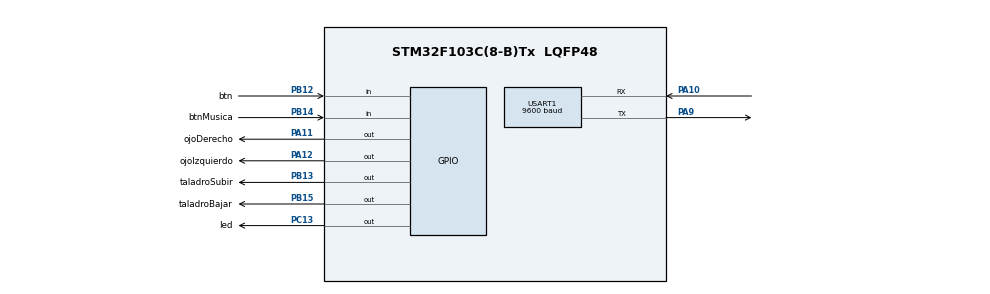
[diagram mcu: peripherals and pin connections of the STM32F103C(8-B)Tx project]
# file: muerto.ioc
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Mcu.Family=STM32F1
Mcu.Name=STM32F103C(8-B)Tx
Mcu.Package=LQFP48
NVIC.PriorityGroup=NVIC_PRIORITYGROUP_4
PA10.Mode=Asynchronous
PA10.Signal=USART1_RX
PA11.GPIO_Label=ojoDerecho
PA11.Signal=GPIO_Output
PA12.GPIO_Label=ojoIzquierdo
PA12.Signal=GPIO_Output
PA13.Mode=Serial_Wire
PA13.Signal=SYS_JTMS-SWDIO
PA14.Mode=Serial_Wire
PA14.Signal=SYS_JTCK-SWCLK
PA9.Mode=Asynchronous
PA9.Signal=USART1_TX
PB12.GPIO_Label=btn
PB12.GPIO_PuPd=GPIO_PULLUP
PB12.Signal=GPIO_Input
PB13.GPIO_Label=taladroSubir
PB13.Signal=GPIO_Output
PB14.GPIO_Label=btnMusica
PB14.GPIO_PuPd=GPIO_PULLUP
PB14.Signal=GPIO_Input
PB15.GPIO_Label=taladroBajar
PB15.Signal=GPIO_Output
PC13-TAMPER-RTC.GPIO_Label=led
PC13-TAMPER-RTC.Signal=GPIO_Output
PD0-OSC_IN.Mode=HSE-External-Oscillator
PD0-OSC_IN.Signal=RCC_OSC_IN
PD1-OSC_OUT.Mode=HSE-External-Oscillator
PD1-OSC_OUT.Signal=RCC_OSC_OUT
ProjectManager.HeapSize=0x200
ProjectManager.StackSize=0x400
ProjectManager.TargetToolchain=STM32CubeIDE
RCC.APB1Freq_Value=8000000
RCC.APB2Freq_Value=8000000
USART1.BaudRate=9600
USART1.VirtualMode=VM_ASYNC
board=custom

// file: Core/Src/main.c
/* USER CODE BEGIN Header */
/**
  ******************************************************************************
  * @file           : main.c
  * @brief          : Main program body
  ******************************************************************************
  * @attention
  *
  * Copyright (c) 2023 STMicroelectronics.
  * All rights reserved.
  *
  * This software is licensed under terms that can be found in the LICENSE file
  * in the root directory of this software component.
  * If no LICENSE file comes with this software, it is provided AS-IS.
  *
  ******************************************************************************
  */
/* USER CODE END Header */
#include "main.h"

/* USER CODE BEGIN Includes */

#include "../librerias/uart.h"
#include "../librerias/dfplayer.h"

/* USER CODE END Includes */

UART_HandleTypeDef huart1;

void SystemClock_Config(void);
static void MX_GPIO_Init(void);
static void MX_USART1_UART_Init(void);

int main(void)
{

  /* MCU Configuration--------------------------------------------------------*/

  /* Reset of all peripherals, Initializes the Flash interface and the Systick. */
  HAL_Init();

  /* Configure the system clock */
  SystemClock_Config();

  /* Initialize all configured peripherals */
  MX_GPIO_Init();
  MX_USART1_UART_Init();
  /* USER CODE BEGIN 2 */
  HAL_GPIO_WritePin(taladroBajar_GPIO_Port, taladroBajar_Pin, 1);
  HAL_GPIO_WritePin(taladroSubir_GPIO_Port, taladroSubir_Pin, 1);
  HAL_GPIO_WritePin(led_GPIO_Port, led_Pin, 1);

  HAL_Delay(500);
   mp3_inicializa();
   HAL_Delay(200);
   mp3_play_x(2);
  /* USER CODE END 2 */

  /* Infinite loop */
   while (1)
      {

    	  if(HAL_GPIO_ReadPin(btn_GPIO_Port, btn_Pin)){
    		  // Si no se presiona el boton todo se desactiva
    		   HAL_GPIO_WritePin(led_GPIO_Port, led_Pin, 1);
    	  		HAL_GPIO_WritePin(taladroBajar_GPIO_Port, taladroBajar_Pin, 1);
    	  		HAL_GPIO_WritePin(taladroSubir_GPIO_Port, taladroSubir_Pin, 1);
    	  		// Ojos apagados
    	  		HAL_GPIO_WritePin(ojoDerecho_GPIO_Port, ojoDerecho_Pin, 0);
    	  		HAL_GPIO_WritePin(ojoIzquierdo_GPIO_Port, ojoIzquierdo_Pin, 0);
    	  	  } else{
    	  		  // Se encienden los ojos
    	  		  HAL_GPIO_WritePin(ojoDerecho_GPIO_Port, ojoDerecho_Pin, 1);
    	  		  HAL_GPIO_WritePin(ojoIzquierdo_GPIO_Port, ojoIzquierdo_Pin, 1);
    	  		  // Se activa el grito
    	  		mp3_play_x(1);

    	  		// Se activa el taladro subir
    	  		HAL_GPIO_WritePin(taladroBajar_GPIO_Port, taladroBajar_Pin, 1);
    	  		HAL_GPIO_WritePin(taladroSubir_GPIO_Port, taladroSubir_Pin, 0);

    	  		// Se espera 110 ms para el levantamiento
    	  		HAL_Delay(90);

    	  		// Ya pasado el tiempo se desactiva
    	  		HAL_GPIO_WritePin(taladroSubir_GPIO_Port, taladroSubir_Pin, 1);

    	  		// Reproduce el grito por 3 segundos
    	  		HAL_Delay(3000);

    	  		// Repite la cancion y baja al mono
    	  		mp3_play_x(2);

    	  		// Se apagan los ojos

    	  		HAL_GPIO_WritePin(ojoDerecho_GPIO_Port, ojoDerecho_Pin, 0);
    	  		HAL_GPIO_WritePin(ojoIzquierdo_GPIO_Port, ojoIzquierdo_Pin, 0);

    	  		// Se activa el taladro bajar
    	  		HAL_GPIO_WritePin(taladroBajar_GPIO_Port, taladroBajar_Pin, 0);
    	  		// 200 ms
    	  		HAL_Delay(145);
    	  		HAL_GPIO_WritePin(taladroBajar_GPIO_Port, taladroBajar_Pin, 1);
    	  	  }

    	  if(!HAL_GPIO_ReadPin(btnMusica_GPIO_Port, btnMusica_Pin)){
    		   mp3_play_x(2);
    	  	  }
      }}

void SystemClock_Config(void)
{
  RCC_OscInitTypeDef RCC_OscInitStruct = {0};
  RCC_ClkInitTypeDef RCC_ClkInitStruct = {0};

  /** Initializes the RCC Oscillators according to the specified parameters
  * in the RCC_OscInitTypeDef structure.
  */
  RCC_OscInitStruct.OscillatorType = RCC_OSCILLATORTYPE_HSI;
  RCC_OscInitStruct.HSIState = RCC_HSI_ON;
  RCC_OscInitStruct.HSICalibrationValue = RCC_HSICALIBRATION_DEFAULT;
  RCC_OscInitStruct.PLL.PLLState = RCC_PLL_NONE;
  if (HAL_RCC_OscConfig(&RCC_OscInitStruct) != HAL_OK)
  {
    Error_Handler();
  }

  /** Initializes the CPU, AHB and APB buses clocks
  */
  RCC_ClkInitStruct.ClockType = RCC_CLOCKTYPE_HCLK|RCC_CLOCKTYPE_SYSCLK
                              |RCC_CLOCKTYPE_PCLK1|RCC_CLOCKTYPE_PCLK2;
  RCC_ClkInitStruct.SYSCLKSource = RCC_SYSCLKSOURCE_HSI;
  RCC_ClkInitStruct.AHBCLKDivider = RCC_SYSCLK_DIV1;
  RCC_ClkInitStruct.APB1CLKDivider = RCC_HCLK_DIV1;
  RCC_ClkInitStruct.APB2CLKDivider = RCC_HCLK_DIV1;

  if (HAL_RCC_ClockConfig(&RCC_ClkInitStruct, FLASH_LATENCY_0) != HAL_OK)
  {
    Error_Handler();
  }
}

static void MX_USART1_UART_Init(void)
{

  huart1.Instance = USART1;
  huart1.Init.BaudRate = 9600;
  huart1.Init.WordLength = UART_WORDLENGTH_8B;
  huart1.Init.StopBits = UART_STOPBITS_1;
  huart1.Init.Parity = UART_PARITY_NONE;
  huart1.Init.Mode = UART_MODE_TX_RX;
  huart1.Init.HwFlowCtl = UART_HWCONTROL_NONE;
  huart1.Init.OverSampling = UART_OVERSAMPLING_16;
  if (HAL_UART_Init(&huart1) != HAL_OK)
  {
    Error_Handler();
  }

}

static void MX_GPIO_Init(void)
{
  GPIO_InitTypeDef GPIO_InitStruct = {0};

  /* GPIO Ports Clock Enable */
  __HAL_RCC_GPIOC_CLK_ENABLE();
  __HAL_RCC_GPIOD_CLK_ENABLE();
  __HAL_RCC_GPIOB_CLK_ENABLE();
  __HAL_RCC_GPIOA_CLK_ENABLE();

  /*Configure GPIO pin Output Level */
  HAL_GPIO_WritePin(led_GPIO_Port, led_Pin, GPIO_PIN_RESET);

  /*Configure GPIO pin Output Level */
  HAL_GPIO_WritePin(GPIOB, taladroSubir_Pin|taladroBajar_Pin, GPIO_PIN_RESET);

  /*Configure GPIO pin Output Level */
  HAL_GPIO_WritePin(GPIOA, ojoDerecho_Pin|ojoIzquierdo_Pin, GPIO_PIN_RESET);

  /*Configure GPIO pin : led_Pin */
  GPIO_InitStruct.Pin = led_Pin;
  GPIO_InitStruct.Mode = GPIO_MODE_OUTPUT_PP;
  GPIO_InitStruct.Pull = GPIO_NOPULL;
  GPIO_InitStruct.Speed = GPIO_SPEED_FREQ_LOW;
  HAL_GPIO_Init(led_GPIO_Port, &GPIO_InitStruct);

  /*Configure GPIO pins : btn_Pin btnMusica_Pin */
  GPIO_InitStruct.Pin = btn_Pin|btnMusica_Pin;
  GPIO_InitStruct.Mode = GPIO_MODE_INPUT;
  GPIO_InitStruct.Pull = GPIO_PULLUP;
  HAL_GPIO_Init(GPIOB, &GPIO_InitStruct);

  /*Configure GPIO pins : taladroSubir_Pin taladroBajar_Pin */
  GPIO_InitStruct.Pin = taladroSubir_Pin|taladroBajar_Pin;
  GPIO_InitStruct.Mode = GPIO_MODE_OUTPUT_PP;
  GPIO_InitStruct.Pull = GPIO_NOPULL;
  GPIO_InitStruct.Speed = GPIO_SPEED_FREQ_LOW;
  HAL_GPIO_Init(GPIOB, &GPIO_InitStruct);

  /*Configure GPIO pins : ojoDerecho_Pin ojoIzquierdo_Pin */
  GPIO_InitStruct.Pin = ojoDerecho_Pin|ojoIzquierdo_Pin;
  GPIO_InitStruct.Mode = GPIO_MODE_OUTPUT_PP;
  GPIO_InitStruct.Pull = GPIO_NOPULL;
  GPIO_InitStruct.Speed = GPIO_SPEED_FREQ_LOW;
  HAL_GPIO_Init(GPIOA, &GPIO_InitStruct);

}

void Error_Handler(void)
{
  __disable_irq();
  while (1)
  {
  }
}
